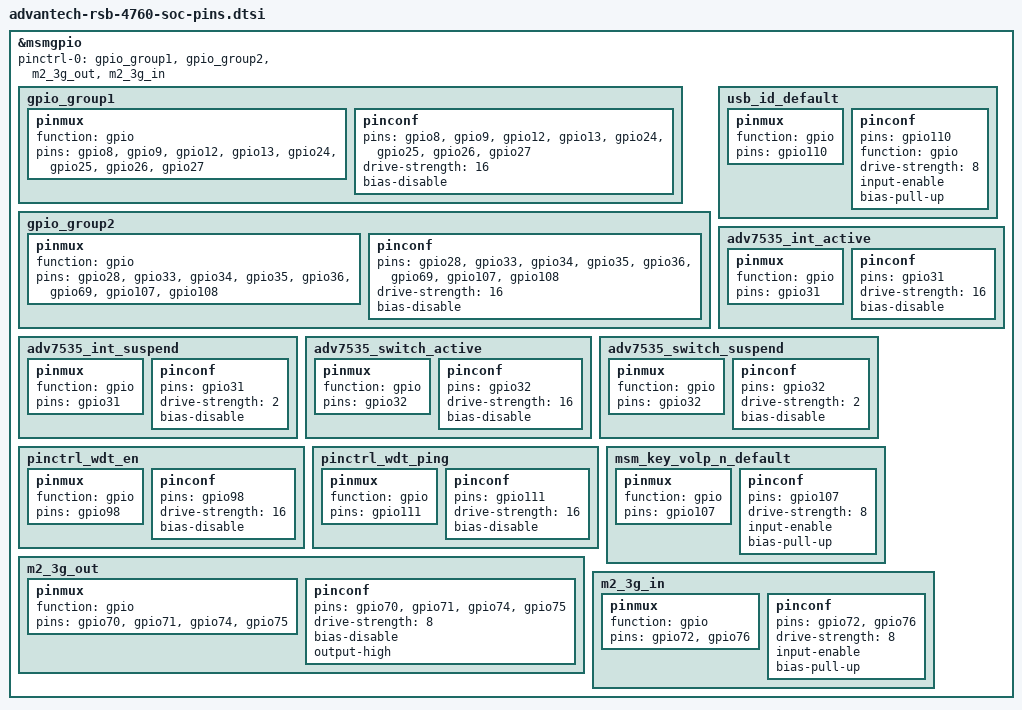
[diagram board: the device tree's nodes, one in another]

#include <dt-bindings/gpio/gpio.h>

&msmgpio {

	pinctrl-names = "default";
	pinctrl-0 = <&gpio_group1 &gpio_group2 &m2_3g_out &m2_3g_in>;

	gpio_group1: gpio_group1 {
		pinmux {
			function = "gpio";
			pins = "gpio8", "gpio9", "gpio12", "gpio13",
				"gpio24", "gpio25", "gpio26", "gpio27";
		};
		pinconf {
			pins = "gpio8", "gpio9", "gpio12", "gpio13",
				"gpio24", "gpio25", "gpio26", "gpio27";
			drive-strength = <16>;
			bias-disable;
		};
	};

	gpio_group2: gpio_group2 {
		pinmux {
			function = "gpio";
			pins = "gpio28", "gpio33", "gpio34", "gpio35",
				"gpio36", "gpio69", "gpio107", "gpio108";
		};
		pinconf {
			pins = "gpio28", "gpio33", "gpio34", "gpio35",
				"gpio36", "gpio69", "gpio107", "gpio108";
			drive-strength = <16>;
			bias-disable;
		};
	};

	usb_id_default: usb_id_default {
		pinmux {
			function = "gpio";
			pins = "gpio110";
		};

		pinconf {
			pins = "gpio110";
			function = "gpio";
			drive-strength = <8>;
			input-enable;
			bias-pull-up;
		};
	};

	adv7535_int_active: adv7535_int_active {
		pinmux {
			function = "gpio";
			pins = "gpio31";
		};
		pinconf {
			pins = "gpio31";
			drive-strength = <16>;
			bias-disable;
		};
	};

	adv7535_int_suspend: adv7535_int_suspend {
		pinmux {
			function = "gpio";
			pins = "gpio31";
		};
		pinconf {
			pins = "gpio31";
			drive-strength = <2>;
			bias-disable;
		};
	};

	adv7535_switch_active: adv7535_switch_active {
		pinmux {
			function = "gpio";
			pins = "gpio32";
		};
		pinconf {
			pins = "gpio32";
			drive-strength = <16>;
			bias-disable;
		};
	};

	adv7535_switch_suspend: adv7535_switch_suspend {
		pinmux {
			function = "gpio";
			pins = "gpio32";
		};
		pinconf {
			pins = "gpio32";
			drive-strength = <2>;
			bias-disable;
		};
	};

	pinctrl_wdt_en: pinctrl_wdt_en {
		pinmux {
			function = "gpio";
			pins = "gpio98";
		};
		pinconf {
			pins = "gpio98";
			drive-strength = <16>;
			bias-disable;
		};
	};

	pinctrl_wdt_ping: pinctrl_wdt_ping  {
		pinmux {
			function = "gpio";
			pins = "gpio111";
		};
		pinconf {
			pins = "gpio111";
			drive-strength = <16>;
			bias-disable;
		};
	};

	msm_key_volp_n_default: msm_key_volp_n_default {
		pinmux {
			function = "gpio";
			pins = "gpio107";
		};
		pinconf {
			pins = "gpio107";
			drive-strength = <8>;
			input-enable;
			bias-pull-up;
		};
	};

	m2_3g_out: m2_3g_out {
		pinmux {
			function = "gpio";
			pins = "gpio70", "gpio71", "gpio74", "gpio75";
		};
		pinconf {
			pins = "gpio70", "gpio71", "gpio74", "gpio75";
			drive-strength = <8>;
			bias-disable;
			output-high;
		};
	};

	m2_3g_in: m2_3g_in {
		pinmux {
			function = "gpio";
			pins = "gpio72", "gpio76";
		};
		pinconf {
			pins = "gpio72", "gpio76";
			drive-strength = <8>;
			input-enable;
			bias-pull-up;
		};
	};
};
